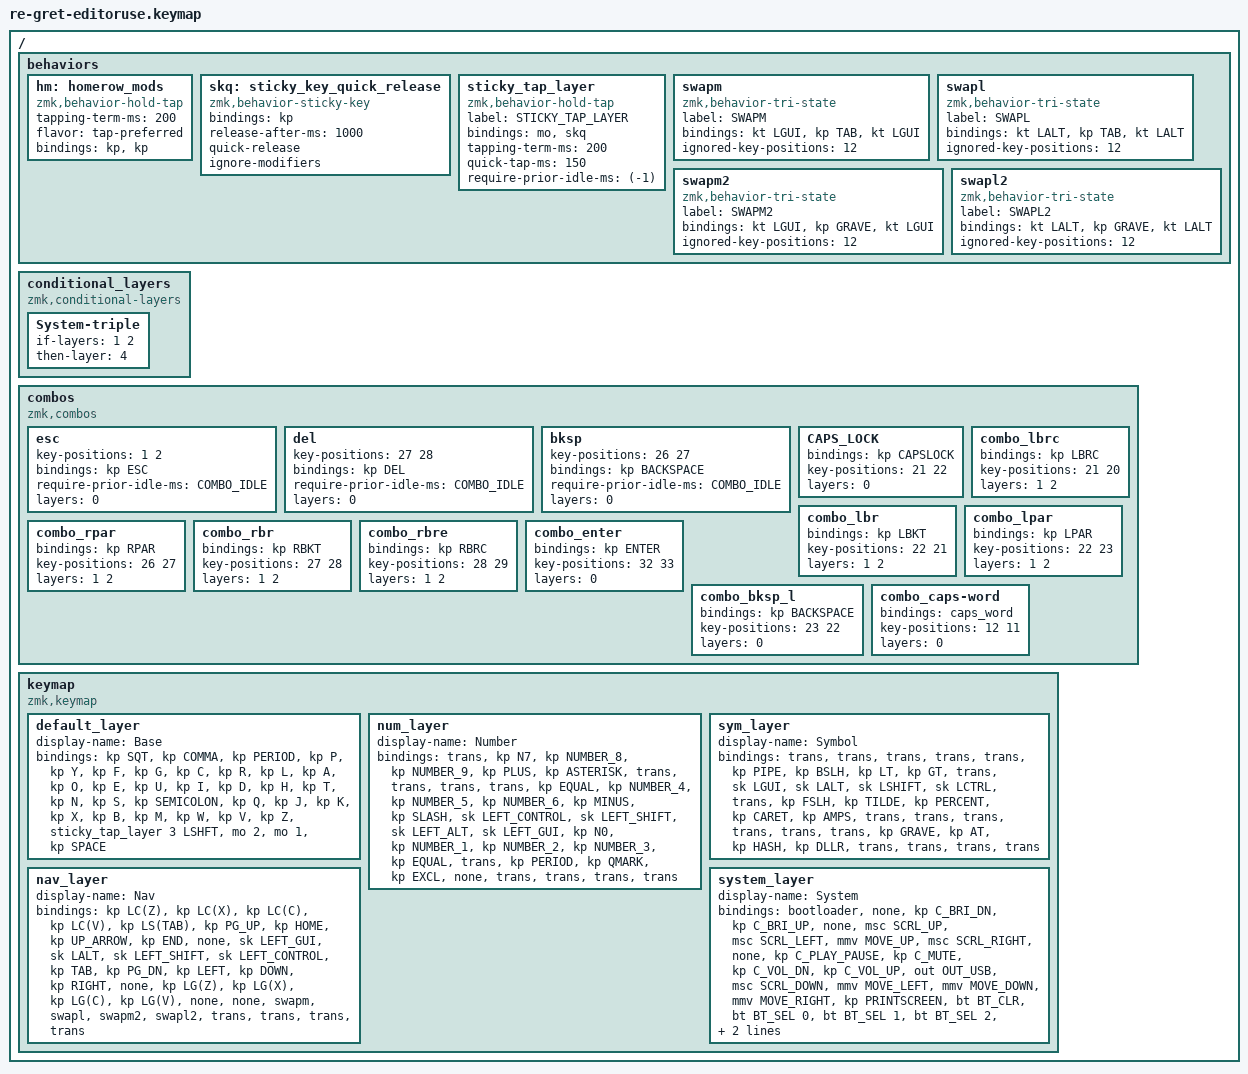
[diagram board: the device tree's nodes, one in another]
#include <behaviors.dtsi>
#include <dt-bindings/zmk/bt.h>
#include <dt-bindings/zmk/keys.h>
#include <dt-bindings/zmk/outputs.h>
#include <dt-bindings/zmk/pointing.h>

#define SYM_L 1
#define NAV_L 2
#define NUM_L 3
#define SYS_L 4

/ {
    behaviors {
        hm: homerow_mods {
            compatible = "zmk,behavior-hold-tap";
            #binding-cells = <2>;
            tapping-term-ms = <200>;
            flavor = "tap-preferred";
            bindings = <&kp>, <&kp>;
        };

        skq: sticky_key_quick_release {
            compatible = "zmk,behavior-sticky-key";
            #binding-cells = <1>;
            bindings = <&kp>;
            release-after-ms = <1000>;
            quick-release;
            ignore-modifiers;
        };

        sticky_tap_layer: sticky_tap_layer {
            compatible = "zmk,behavior-hold-tap";
            label = "STICKY_TAP_LAYER";
            bindings = <&mo>, <&skq>;

            #binding-cells = <2>;
            tapping-term-ms = <200>;
            quick-tap-ms = <150>;
            require-prior-idle-ms = <(-1)>;
        };

        swapm: swapm {
            compatible = "zmk,behavior-tri-state";
            label = "SWAPM";
            #binding-cells = <0>;
            bindings = <&kt LGUI>, <&kp TAB>, <&kt LGUI>;

            ignored-key-positions = <12>;
        };

        swapl: swapl {
            compatible = "zmk,behavior-tri-state";
            label = "SWAPL";
            #binding-cells = <0>;
            bindings = <&kt LALT>, <&kp TAB>, <&kt LALT>;

            ignored-key-positions = <12>;
        };

        swapm2: swapm2 {
            compatible = "zmk,behavior-tri-state";
            label = "SWAPM2";
            #binding-cells = <0>;
            bindings = <&kt LGUI>, <&kp GRAVE>, <&kt LGUI>;

            ignored-key-positions = <12>;
        };

        swapl2: swapl2 {
            compatible = "zmk,behavior-tri-state";
            label = "SWAPL2";
            #binding-cells = <0>;
            bindings = <&kt LALT>, <&kp GRAVE>, <&kt LALT>;

            ignored-key-positions = <12>;
        };
    };

    conditional_layers {
        compatible = "zmk,conditional-layers";

        System-triple {
            if-layers = <1 2>;
            then-layer = <4>;
        };
    };

    #define COMBO_IDLE 175

    combos {
        compatible = "zmk,combos";

        // Activate system layer on inner thumbs

        esc {
            key-positions = <1 2>;
            bindings = <&kp ESC>;
            require-prior-idle-ms = <COMBO_IDLE>;
            layers = <0>;
        };

        del {
            key-positions = <27 28>;
            bindings = <&kp DEL>;
            require-prior-idle-ms = <COMBO_IDLE>;
            layers = <0>;
        };

        bksp {
            key-positions = <26 27>;
            bindings = <&kp BACKSPACE>;
            require-prior-idle-ms = <COMBO_IDLE>;
            layers = <0>;
        };

        CAPS_LOCK {
            bindings = <&kp CAPSLOCK>;
            key-positions = <21 22>;
            layers = <0>;
        };

        combo_lbrc {
            bindings = <&kp LBRC>;
            key-positions = <21 20>;
            layers = <1 2>;
        };

        combo_lbr {
            bindings = <&kp LBKT>;
            key-positions = <22 21>;
            layers = <1 2>;
        };

        combo_lpar {
            bindings = <&kp LPAR>;
            key-positions = <22 23>;
            layers = <1 2>;
        };

        combo_rpar {
            bindings = <&kp RPAR>;
            key-positions = <26 27>;
            layers = <1 2>;
        };

        combo_rbr {
            bindings = <&kp RBKT>;
            key-positions = <27 28>;
            layers = <1 2>;
        };

        combo_rbre {
            bindings = <&kp RBRC>;
            key-positions = <28 29>;
            layers = <1 2>;
        };

        combo_enter {
            bindings = <&kp ENTER>;
            key-positions = <32 33>;
            layers = <0>;
        };

        combo_bksp_l {
            bindings = <&kp BACKSPACE>;
            key-positions = <23 22>;
            layers = <0>;
        };

        combo_caps-word {
            bindings = <&caps_word>;
            key-positions = <12 11>;
            layers = <0>;
        };
    };

    keymap {
        compatible = "zmk,keymap";

        default_layer {
            display-name = "Base";
            bindings = <
&kp SQT  &kp COMMA  &kp PERIOD  &kp P  &kp Y  &kp F  &kp G  &kp C  &kp R  &kp L  &kp A  &kp O  &kp E  &kp U  &kp I  &kp D  &kp H  &kp T  &kp N  &kp S  &kp SEMICOLON  &kp Q  &kp J  &kp K  &kp X  &kp B  &kp M  &kp W  &kp V  &kp Z  &sticky_tap_layer 3 LSHFT  &mo 2  &mo 1  &kp SPACE
            >;
        };

        num_layer {
            display-name = "Number";
            bindings = <
&trans  &kp N7  &kp NUMBER_8  &kp NUMBER_9  &kp PLUS  &kp ASTERISK  &trans  &trans  &trans  &trans  &kp EQUAL  &kp NUMBER_4  &kp NUMBER_5  &kp NUMBER_6  &kp MINUS  &kp SLASH  &sk LEFT_CONTROL  &sk LEFT_SHIFT  &sk LEFT_ALT  &sk LEFT_GUI  &kp N0  &kp NUMBER_1  &kp NUMBER_2  &kp NUMBER_3  &kp EQUAL  &trans  &kp PERIOD  &kp QMARK  &kp EXCL  &none  &trans  &trans  &trans  &trans
            >;
        };

        sym_layer {
            display-name = "Symbol";
            bindings = <
&trans  &trans  &trans  &trans  &trans  &kp PIPE  &kp BSLH  &kp LT  &kp GT  &trans  &sk LGUI  &sk LALT  &sk LSHIFT  &sk LCTRL  &trans  &kp FSLH  &kp TILDE  &kp PERCENT  &kp CARET  &kp AMPS  &trans  &trans  &trans  &trans  &trans  &trans  &kp GRAVE  &kp AT  &kp HASH  &kp DLLR  &trans  &trans  &trans  &trans
            >;
        };

        nav_layer {
            display-name = "Nav";
            bindings = <
&kp LC(Z)  &kp LC(X)  &kp LC(C)  &kp LC(V)  &kp LS(TAB)  &kp PG_UP  &kp HOME  &kp UP_ARROW  &kp END  &none  &sk LEFT_GUI  &sk LALT  &sk LEFT_SHIFT  &sk LEFT_CONTROL  &kp TAB  &kp PG_DN  &kp LEFT  &kp DOWN  &kp RIGHT  &none  &kp LG(Z)  &kp LG(X)  &kp LG(C)  &kp LG(V)  &none  &none  &swapm  &swapl  &swapm2  &swapl2  &trans  &trans  &trans  &trans
            >;
        };

        system_layer {
            display-name = "System";
            bindings = <
&bootloader  &none  &kp C_BRI_DN  &kp C_BRI_UP  &none  &msc SCRL_UP  &msc SCRL_LEFT  &mmv MOVE_UP  &msc SCRL_RIGHT  &none  &kp C_PLAY_PAUSE  &kp C_MUTE  &kp C_VOL_DN  &kp C_VOL_UP  &out OUT_USB  &msc SCRL_DOWN  &mmv MOVE_LEFT  &mmv MOVE_DOWN  &mmv MOVE_RIGHT  &kp PRINTSCREEN  &bt BT_CLR  &bt BT_SEL 0  &bt BT_SEL 1  &bt BT_SEL 2  &out OUT_BLE  &none  &mkp LCLK  &mkp MCLK  &mkp RCLK  &none  &trans  &trans  &trans  &trans
            >;
        };
    };
};
